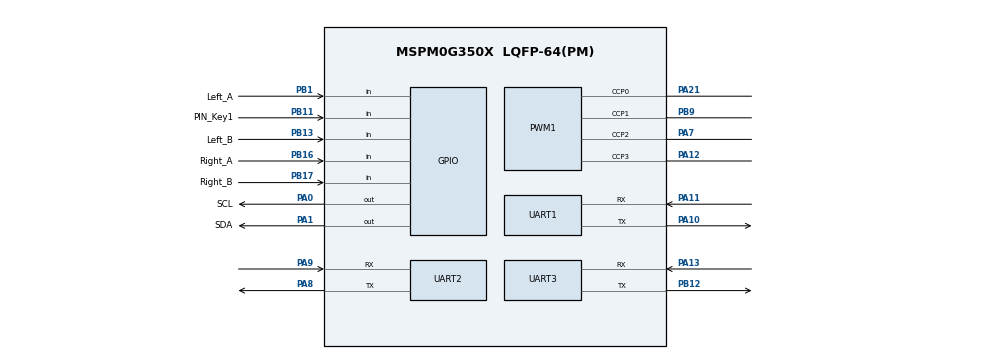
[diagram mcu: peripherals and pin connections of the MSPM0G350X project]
/**
 * @cliArgs --device "MSPM0G350X" --part "Default" --package "LQFP-64(PM)" --product "mspm0_sdk@2.10.00.04"
 * @versions {"tool":"1.26.2+4477"}
 */

/**
 * Import the modules used in this configuration.
 */
const ADC12   = scripting.addModule("/ti/driverlib/ADC12", {}, false);
const ADC121  = ADC12.addInstance();
const GPIO    = scripting.addModule("/ti/driverlib/GPIO", {}, false);
const GPIO1   = GPIO.addInstance();
const GPIO2   = GPIO.addInstance();
const GPIO3   = GPIO.addInstance();
const GPIO4   = GPIO.addInstance();
const GPIO5   = GPIO.addInstance();
const GPIO6   = GPIO.addInstance();
const PWM     = scripting.addModule("/ti/driverlib/PWM", {}, false);
const PWM1    = PWM.addInstance();
const SYSCTL  = scripting.addModule("/ti/driverlib/SYSCTL");
const SYSTICK = scripting.addModule("/ti/driverlib/SYSTICK");
const TIMER   = scripting.addModule("/ti/driverlib/TIMER", {}, false);
const TIMER1  = TIMER.addInstance();
const TIMER2  = TIMER.addInstance();
const UART    = scripting.addModule("/ti/driverlib/UART", {}, false);
const UART1   = UART.addInstance();
const UART2   = UART.addInstance();
const UART3   = UART.addInstance();
const UART4   = UART.addInstance();

/**
 * Write custom configuration values to the imported modules.
 */
const divider6       = system.clockTree["PLL_CLK2X_DIV"];
divider6.divideValue = 4;

const divider7       = system.clockTree["PLL_PDIV"];
divider7.divideValue = 2;

const divider9       = system.clockTree["UDIV"];
divider9.divideValue = 2;

const gate7  = system.clockTree["MFCLKGATE"];
gate7.enable = true;

const multiplier2         = system.clockTree["PLL_QDIV"];
multiplier2.multiplyValue = 10;

const mux8       = system.clockTree["HSCLKMUX"];
mux8.inputSelect = "HSCLKMUX_SYSPLL2X";

ADC121.$name               = "ADC12_0";
ADC121.adcPin0Config.$name = "ti_driverlib_gpio_GPIOPinGeneric8";

const Board = scripting.addModule("/ti/driverlib/Board", {}, false);

GPIO1.$name                              = "LED1";
GPIO1.port                               = "PORTA";
GPIO1.associatedPins[0].$name            = "PIN_14";
GPIO1.associatedPins[0].internalResistor = "PULL_DOWN";
GPIO1.associatedPins[0].assignedPin      = "14";

GPIO2.$name                              = "KEY";
GPIO2.port                               = "PORTB";
GPIO2.associatedPins.create(4);
GPIO2.associatedPins[0].direction        = "INPUT";
GPIO2.associatedPins[0].interruptEn      = true;
GPIO2.associatedPins[0].polarity         = "RISE";
GPIO2.associatedPins[0].internalResistor = "PULL_UP";
GPIO2.associatedPins[0].$name            = "PIN_Key1";
GPIO2.associatedPins[0].assignedPin      = "11";
GPIO2.associatedPins[0].pin.$assign      = "PB11";
GPIO2.associatedPins[1].direction        = "INPUT";
GPIO2.associatedPins[1].assignedPin      = "0";
GPIO2.associatedPins[1].internalResistor = "PULL_UP";
GPIO2.associatedPins[1].$name            = "PIN_Key2";
GPIO2.associatedPins[2].direction        = "INPUT";
GPIO2.associatedPins[2].assignedPin      = "7";
GPIO2.associatedPins[2].internalResistor = "PULL_UP";
GPIO2.associatedPins[2].$name            = "PIN_Key3";
GPIO2.associatedPins[3].$name            = "PIN_Key4";
GPIO2.associatedPins[3].direction        = "INPUT";
GPIO2.associatedPins[3].assignedPin      = "10";
GPIO2.associatedPins[3].internalResistor = "PULL_UP";

GPIO3.$name                          = "OLED";
GPIO3.port                           = "PORTA";
GPIO3.associatedPins.create(2);
GPIO3.associatedPins[0].$name        = "SCL";
GPIO3.associatedPins[0].initialValue = "SET";
GPIO3.associatedPins[0].ioStructure  = "OD";
GPIO3.associatedPins[0].assignedPin  = "0";
GPIO3.associatedPins[0].pin.$assign  = "PA0";
GPIO3.associatedPins[1].$name        = "SDA";
GPIO3.associatedPins[1].ioStructure  = "OD";
GPIO3.associatedPins[1].initialValue = "SET";
GPIO3.associatedPins[1].assignedPin  = "1";
GPIO3.associatedPins[1].pin.$assign  = "PA1";

GPIO4.$name                          = "TB6612";
GPIO4.port                           = "PORTA";
GPIO4.associatedPins.create(4);
GPIO4.associatedPins[0].initialValue = "SET";
GPIO4.associatedPins[0].assignedPin  = "26";
GPIO4.associatedPins[0].$name        = "ZUO_IN1";
GPIO4.associatedPins[1].initialValue = "SET";
GPIO4.associatedPins[1].assignedPin  = "24";
GPIO4.associatedPins[1].$name        = "ZUO_IN2";
GPIO4.associatedPins[2].initialValue = "SET";
GPIO4.associatedPins[2].assignedPin  = "22";
GPIO4.associatedPins[2].$name        = "YOU_IN1";
GPIO4.associatedPins[3].initialValue = "SET";
GPIO4.associatedPins[3].assignedPin  = "15";
GPIO4.associatedPins[3].$name        = "YOU_IN2";

GPIO5.port                               = "PORTB";
GPIO5.$name                              = "ENCODER";
GPIO5.associatedPins.create(4);
GPIO5.associatedPins[0].direction        = "INPUT";
GPIO5.associatedPins[0].interruptEn      = true;
GPIO5.associatedPins[0].$name            = "Left_A";
GPIO5.associatedPins[0].internalResistor = "PULL_UP";
GPIO5.associatedPins[0].polarity         = "RISE";
GPIO5.associatedPins[0].assignedPin      = "1";
GPIO5.associatedPins[0].pin.$assign      = "PB1";
GPIO5.associatedPins[1].direction        = "INPUT";
GPIO5.associatedPins[1].assignedPin      = "13";
GPIO5.associatedPins[1].polarity         = "FALL";
GPIO5.associatedPins[1].$name            = "Left_B";
GPIO5.associatedPins[1].internalResistor = "PULL_UP";
GPIO5.associatedPins[1].pin.$assign      = "PB13";
GPIO5.associatedPins[2].direction        = "INPUT";
GPIO5.associatedPins[2].assignedPin      = "16";
GPIO5.associatedPins[2].interruptEn      = true;
GPIO5.associatedPins[2].internalResistor = "PULL_UP";
GPIO5.associatedPins[2].polarity         = "RISE";
GPIO5.associatedPins[2].$name            = "Right_A";
GPIO5.associatedPins[2].pin.$assign      = "PB16";
GPIO5.associatedPins[3].direction        = "INPUT";
GPIO5.associatedPins[3].internalResistor = "PULL_UP";
GPIO5.associatedPins[3].polarity         = "FALL";
GPIO5.associatedPins[3].assignedPin      = "17";
GPIO5.associatedPins[3].$name            = "Right_B";
GPIO5.associatedPins[3].pin.$assign      = "PB17";

GPIO6.$name                          = "Huidu";
GPIO6.associatedPins.create(8);
GPIO6.associatedPins[0].$name        = "L4";
GPIO6.associatedPins[0].direction    = "INPUT";
GPIO6.associatedPins[0].assignedPort = "PORTB";
GPIO6.associatedPins[0].assignedPin  = "25";
GPIO6.associatedPins[1].$name        = "L3";
GPIO6.associatedPins[1].direction    = "INPUT";
GPIO6.associatedPins[1].assignedPort = "PORTB";
GPIO6.associatedPins[1].assignedPin  = "8";
GPIO6.associatedPins[2].$name        = "L2";
GPIO6.associatedPins[2].direction    = "INPUT";
GPIO6.associatedPins[2].assignedPort = "PORTB";
GPIO6.associatedPins[2].assignedPin  = "23";
GPIO6.associatedPins[3].$name        = "L1";
GPIO6.associatedPins[3].direction    = "INPUT";
GPIO6.associatedPins[3].assignedPort = "PORTB";
GPIO6.associatedPins[3].assignedPin  = "6";
GPIO6.associatedPins[4].$name        = "R1";
GPIO6.associatedPins[4].direction    = "INPUT";
GPIO6.associatedPins[4].assignedPort = "PORTB";
GPIO6.associatedPins[4].assignedPin  = "5";
GPIO6.associatedPins[5].$name        = "R2";
GPIO6.associatedPins[5].direction    = "INPUT";
GPIO6.associatedPins[5].assignedPort = "PORTB";
GPIO6.associatedPins[5].assignedPin  = "20";
GPIO6.associatedPins[6].$name        = "R3";
GPIO6.associatedPins[6].direction    = "INPUT";
GPIO6.associatedPins[6].assignedPort = "PORTB";
GPIO6.associatedPins[6].assignedPin  = "19";
GPIO6.associatedPins[7].$name        = "R4";
GPIO6.associatedPins[7].direction    = "INPUT";
GPIO6.associatedPins[7].assignedPort = "PORTB";
GPIO6.associatedPins[7].assignedPin  = "4";

PWM1.$name                              = "PWM_A0";
PWM1.clockDivider                       = 8;
PWM1.pwmMode                            = "EDGE_ALIGN_UP";
PWM1.ccIndex                            = [0,1,2,3];
PWM1.timerStartTimer                    = true;
PWM1.PWM_CHANNEL_0.$name                = "ti_driverlib_pwm_PWMTimerCC0";
PWM1.PWM_CHANNEL_1.$name                = "ti_driverlib_pwm_PWMTimerCC1";
PWM1.ccp0PinConfig.direction            = scripting.forceWrite("OUTPUT");
PWM1.ccp0PinConfig.hideOutputInversion  = scripting.forceWrite(false);
PWM1.ccp0PinConfig.onlyInternalResistor = scripting.forceWrite(false);
PWM1.ccp0PinConfig.passedPeripheralType = scripting.forceWrite("Digital");
PWM1.ccp0PinConfig.$name                = "ti_driverlib_gpio_GPIOPinGeneric2";
PWM1.ccp1PinConfig.direction            = scripting.forceWrite("OUTPUT");
PWM1.ccp1PinConfig.hideOutputInversion  = scripting.forceWrite(false);
PWM1.ccp1PinConfig.onlyInternalResistor = scripting.forceWrite(false);
PWM1.ccp1PinConfig.passedPeripheralType = scripting.forceWrite("Digital");
PWM1.ccp1PinConfig.$name                = "ti_driverlib_gpio_GPIOPinGeneric3";
PWM1.peripheral.$assign                 = "TIMA0";
PWM1.peripheral.ccp0Pin.$assign         = "PA21";
PWM1.peripheral.ccp1Pin.$assign         = "PB9";
PWM1.peripheral.ccp2Pin.$assign         = "PA7";
PWM1.peripheral.ccp3Pin.$assign         = "PA12";
PWM1.PWM_CHANNEL_2.$name                = "ti_driverlib_pwm_PWMTimerCC2";
PWM1.PWM_CHANNEL_2.invert               = true;
PWM1.PWM_CHANNEL_3.$name                = "ti_driverlib_pwm_PWMTimerCC3";
PWM1.PWM_CHANNEL_3.invert               = true;
PWM1.ccp2PinConfig.$name                = "ti_driverlib_gpio_GPIOPinGeneric4";
PWM1.ccp3PinConfig.$name                = "ti_driverlib_gpio_GPIOPinGeneric5";

SYSCTL.forceDefaultClkConfig = true;
SYSCTL.clockTreeEn           = true;

SYSTICK.interruptPriority = "3";
SYSTICK.period            = 32000;
SYSTICK.systickEnable     = true;
SYSTICK.periodEnable      = true;
SYSTICK.interruptEnable   = true;

TIMER1.timerClkDiv      = 8;
TIMER1.timerStartTimer  = true;
TIMER1.timerMode        = "PERIODIC";
TIMER1.timerClkPrescale = 40;
TIMER1.$name            = "TIMER_A1_KONG_ZHI";
TIMER1.interrupts       = ["ZERO"];
TIMER1.interruptPriority = "2";
TIMER1.timerPeriod      = "0.01";

TIMER2.$name              = "TIMER_Count";
TIMER2.timerClkDiv        = 2;
TIMER2.timerMode          = "PERIODIC";
TIMER2.timerPeriod        = "1 ms";
TIMER2.timerStartTimer    = true;
TIMER2.interruptPriority  = "3";
TIMER2.peripheral.$assign = "TIMG6";

UART1.$name                    = "UART_0";
UART1.uartClkSrc               = "MFCLK";
UART1.enabledInterrupts        = ["RX"];
UART1.targetBaudRate           = 115200;
UART1.interruptPriority        = "3";
UART1.peripheral.$assign       = "UART0";
UART1.peripheral.rxPin.$assign = "PA11";
UART1.peripheral.txPin.$assign = "PA10";
UART1.txPinConfig.$name        = "ti_driverlib_gpio_GPIOPinGeneric0";
UART1.rxPinConfig.$name        = "ti_driverlib_gpio_GPIOPinGeneric1";

UART2.$name                            = "UART_1_pid";
UART2.targetBaudRate                   = 115200;
UART2.enableFIFO                       = true;
UART2.rxFifoThreshold                  = "DL_UART_RX_FIFO_LEVEL_ONE_ENTRY";
UART2.enableDMARX                      = false;
UART2.enableDMATX                      = false;
UART2.peripheral.$assign               = "UART1";
UART2.peripheral.rxPin.$assign         = "PA9";
UART2.peripheral.txPin.$assign         = "PA8";
UART2.txPinConfig.direction            = scripting.forceWrite("OUTPUT");
UART2.txPinConfig.hideOutputInversion  = scripting.forceWrite(false);
UART2.txPinConfig.onlyInternalResistor = scripting.forceWrite(false);
UART2.txPinConfig.passedPeripheralType = scripting.forceWrite("Digital");
UART2.txPinConfig.$name                = "ti_driverlib_gpio_GPIOPinGeneric6";
UART2.txPinConfig.enableConfig         = true;
UART2.rxPinConfig.hideOutputInversion  = scripting.forceWrite(false);
UART2.rxPinConfig.onlyInternalResistor = scripting.forceWrite(false);
UART2.rxPinConfig.passedPeripheralType = scripting.forceWrite("Digital");
UART2.rxPinConfig.$name                = "ti_driverlib_gpio_GPIOPinGeneric7";

UART3.$name                            = "IMU601";
UART3.targetBaudRate                   = 115200;
UART3.enabledInterrupts                = ["RX"];
UART3.interruptPriority                = "3";
UART3.peripheral.$assign               = "UART3";
UART3.peripheral.rxPin.$assign         = "PA13";
UART3.peripheral.txPin.$assign         = "PB12";
UART3.txPinConfig.direction            = scripting.forceWrite("OUTPUT");
UART3.txPinConfig.hideOutputInversion  = scripting.forceWrite(false);
UART3.txPinConfig.onlyInternalResistor = scripting.forceWrite(false);
UART3.txPinConfig.passedPeripheralType = scripting.forceWrite("Digital");
UART3.txPinConfig.$name                = "ti_driverlib_gpio_GPIOPinGeneric9";
UART3.rxPinConfig.hideOutputInversion  = scripting.forceWrite(false);
UART3.rxPinConfig.onlyInternalResistor = scripting.forceWrite(false);
UART3.rxPinConfig.passedPeripheralType = scripting.forceWrite("Digital");
UART3.rxPinConfig.$name                = "ti_driverlib_gpio_GPIOPinGeneric10";
UART3.rxPinConfig.enableConfig         = true;
UART3.rxPinConfig.internalResistor     = "PULL_UP";

UART4.$name                            = "maxicam";
UART4.peripheral.$assign               = "UART2";
UART4.txPinConfig.direction            = scripting.forceWrite("OUTPUT");
UART4.txPinConfig.hideOutputInversion  = scripting.forceWrite(false);
UART4.txPinConfig.onlyInternalResistor = scripting.forceWrite(false);
UART4.txPinConfig.passedPeripheralType = scripting.forceWrite("Digital");
UART4.txPinConfig.$name                = "ti_driverlib_gpio_GPIOPinGeneric11";
UART4.rxPinConfig.hideOutputInversion  = scripting.forceWrite(false);
UART4.rxPinConfig.onlyInternalResistor = scripting.forceWrite(false);
UART4.rxPinConfig.passedPeripheralType = scripting.forceWrite("Digital");
UART4.rxPinConfig.$name                = "ti_driverlib_gpio_GPIOPinGeneric12";

/**
 * Pinmux solution for unlocked pins/peripherals. This ensures that minor changes to the automatic solver in a future
 * version of the tool will not impact the pinmux you originally saw.  These lines can be completely deleted in order to
 * re-solve from scratch.
 */
ADC121.peripheral.$suggestSolution           = "ADC0";
ADC121.peripheral.adcPin0.$suggestSolution   = "PA27";
Board.peripheral.$suggestSolution            = "DEBUGSS";
Board.peripheral.swclkPin.$suggestSolution   = "PA20";
Board.peripheral.swdioPin.$suggestSolution   = "PA19";
GPIO1.associatedPins[0].pin.$suggestSolution = "PA14";
GPIO2.associatedPins[1].pin.$suggestSolution = "PB0";
GPIO2.associatedPins[2].pin.$suggestSolution = "PB7";
GPIO2.associatedPins[3].pin.$suggestSolution = "PB10";
GPIO4.associatedPins[0].pin.$suggestSolution = "PA26";
GPIO4.associatedPins[1].pin.$suggestSolution = "PA24";
GPIO4.associatedPins[2].pin.$suggestSolution = "PA22";
GPIO4.associatedPins[3].pin.$suggestSolution = "PA15";
GPIO6.associatedPins[0].pin.$suggestSolution = "PB25";
GPIO6.associatedPins[1].pin.$suggestSolution = "PB8";
GPIO6.associatedPins[2].pin.$suggestSolution = "PB23";
GPIO6.associatedPins[3].pin.$suggestSolution = "PB6";
GPIO6.associatedPins[4].pin.$suggestSolution = "PB5";
GPIO6.associatedPins[5].pin.$suggestSolution = "PB20";
GPIO6.associatedPins[6].pin.$suggestSolution = "PB19";
GPIO6.associatedPins[7].pin.$suggestSolution = "PB4";
TIMER1.peripheral.$suggestSolution           = "TIMA1";
UART4.peripheral.rxPin.$suggestSolution      = "PB18";
UART4.peripheral.txPin.$suggestSolution      = "PA23";
